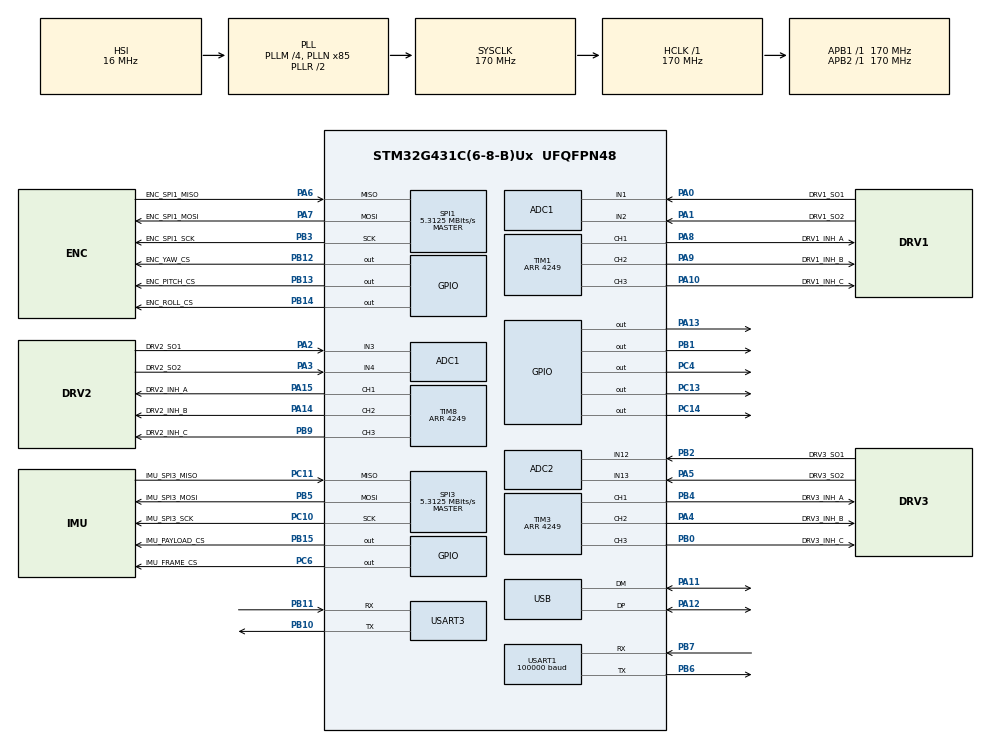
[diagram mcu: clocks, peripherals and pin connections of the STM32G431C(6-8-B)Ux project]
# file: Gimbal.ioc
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ADC1.DMAContinuousRequests=DISABLE
ADC1.EOCSelection=ADC_EOC_SEQ_CONV
ADC1.EnableInjectedConversion=ENABLE
ADC1.EnableRegularConversion=DISABLE
ADC1.ExternalTrigInjecConv=ADC_EXTERNALTRIGINJEC_T1_TRGO
ADC1.InjNumberOfConversion=2
ADC1.InjectedChannel-4\#ChannelInjectedConversion=ADC_CHANNEL_1
ADC1.InjectedChannel-5\#ChannelInjectedConversion=ADC_CHANNEL_2
ADC1.InjectedOffsetNumber-4\#ChannelInjectedConversion=ADC_OFFSET_NONE
ADC1.InjectedOffsetNumber-5\#ChannelInjectedConversion=ADC_OFFSET_NONE
ADC1.InjectedRank-4\#ChannelInjectedConversion=1
ADC1.InjectedRank-5\#ChannelInjectedConversion=2
ADC1.InjectedSamplingTime-4\#ChannelInjectedConversion=ADC_SAMPLETIME_12CYCLES_5
ADC1.InjectedSamplingTime-5\#ChannelInjectedConversion=ADC_SAMPLETIME_12CYCLES_5
ADC1.Overrun=ADC_OVR_DATA_OVERWRITTEN
ADC1.Rank1_Channel=ADC_CHANNEL_1
ADC1.Rank2_Channel=ADC_CHANNEL_2
ADC1.master=1
ADC2.EOCSelection=ADC_EOC_SEQ_CONV
ADC2.EnableInjectedConversion=ENABLE
ADC2.EnableRegularConversion=DISABLE
ADC2.ExternalTrigInjecConv=ADC_EXTERNALTRIGINJEC_T1_TRGO
ADC2.InjNumberOfConversion=2
ADC2.InjectedChannel-3\#ChannelInjectedConversion=ADC_CHANNEL_12
ADC2.InjectedChannel-4\#ChannelInjectedConversion=ADC_CHANNEL_13
ADC2.InjectedOffsetNumber-3\#ChannelInjectedConversion=ADC_OFFSET_NONE
ADC2.InjectedOffsetNumber-4\#ChannelInjectedConversion=ADC_OFFSET_NONE
ADC2.InjectedRank-3\#ChannelInjectedConversion=1
ADC2.InjectedRank-4\#ChannelInjectedConversion=2
ADC2.InjectedSamplingTime-3\#ChannelInjectedConversion=ADC_SAMPLETIME_12CYCLES_5
ADC2.InjectedSamplingTime-4\#ChannelInjectedConversion=ADC_SAMPLETIME_12CYCLES_5
ADC2.Rank1_Channel=ADC_CHANNEL_12
ADC2.Rank2_Channel=ADC_CHANNEL_13
Dma.Request0=SPI1_RX
Dma.Request1=SPI1_TX
Dma.Request2=SPI3_RX
Dma.Request3=SPI3_TX
Dma.Request4=USART1_RX
Dma.SPI1_RX.0.Direction=DMA_PERIPH_TO_MEMORY
Dma.SPI1_RX.0.EventEnable=DISABLE
Dma.SPI1_RX.0.Instance=DMA1_Channel1
Dma.SPI1_RX.0.MemDataAlignment=DMA_MDATAALIGN_HALFWORD
Dma.SPI1_RX.0.MemInc=DMA_MINC_ENABLE
Dma.SPI1_RX.0.Mode=DMA_NORMAL
Dma.SPI1_RX.0.PeriphDataAlignment=DMA_PDATAALIGN_HALFWORD
Dma.SPI1_RX.0.PeriphInc=DMA_PINC_DISABLE
Dma.SPI1_RX.0.Polarity=HAL_DMAMUX_REQ_GEN_RISING
Dma.SPI1_RX.0.Priority=DMA_PRIORITY_LOW
Dma.SPI1_RX.0.RequestNumber=1
Dma.SPI1_RX.0.SignalID=NONE
Dma.SPI1_RX.0.SyncEnable=DISABLE
Dma.SPI1_RX.0.SyncPolarity=HAL_DMAMUX_SYNC_NO_EVENT
Dma.SPI1_RX.0.SyncRequestNumber=1
Dma.SPI1_RX.0.SyncSignalID=NONE
Dma.SPI1_TX.1.Direction=DMA_MEMORY_TO_PERIPH
Dma.SPI1_TX.1.EventEnable=DISABLE
Dma.SPI1_TX.1.Instance=DMA1_Channel2
Dma.SPI1_TX.1.MemDataAlignment=DMA_MDATAALIGN_HALFWORD
Dma.SPI1_TX.1.MemInc=DMA_MINC_ENABLE
Dma.SPI1_TX.1.Mode=DMA_NORMAL
Dma.SPI1_TX.1.PeriphDataAlignment=DMA_PDATAALIGN_HALFWORD
Dma.SPI1_TX.1.PeriphInc=DMA_PINC_DISABLE
Dma.SPI1_TX.1.Polarity=HAL_DMAMUX_REQ_GEN_RISING
Dma.SPI1_TX.1.Priority=DMA_PRIORITY_LOW
Dma.SPI1_TX.1.RequestNumber=1
Dma.SPI1_TX.1.SignalID=NONE
Dma.SPI1_TX.1.SyncEnable=DISABLE
Dma.SPI1_TX.1.SyncPolarity=HAL_DMAMUX_SYNC_NO_EVENT
Dma.SPI1_TX.1.SyncRequestNumber=1
Dma.SPI1_TX.1.SyncSignalID=NONE
Dma.SPI3_RX.2.Direction=DMA_PERIPH_TO_MEMORY
Dma.SPI3_RX.2.EventEnable=DISABLE
Dma.SPI3_RX.2.Instance=DMA1_Channel3
Dma.SPI3_RX.2.MemDataAlignment=DMA_MDATAALIGN_BYTE
Dma.SPI3_RX.2.MemInc=DMA_MINC_ENABLE
Dma.SPI3_RX.2.Mode=DMA_NORMAL
Dma.SPI3_RX.2.PeriphDataAlignment=DMA_PDATAALIGN_BYTE
Dma.SPI3_RX.2.PeriphInc=DMA_PINC_DISABLE
Dma.SPI3_RX.2.Polarity=HAL_DMAMUX_REQ_GEN_RISING
Dma.SPI3_RX.2.Priority=DMA_PRIORITY_LOW
Dma.SPI3_RX.2.RequestNumber=1
Dma.SPI3_RX.2.SignalID=NONE
Dma.SPI3_RX.2.SyncEnable=DISABLE
Dma.SPI3_RX.2.SyncPolarity=HAL_DMAMUX_SYNC_NO_EVENT
Dma.SPI3_RX.2.SyncRequestNumber=1
Dma.SPI3_RX.2.SyncSignalID=NONE
Dma.SPI3_TX.3.Direction=DMA_MEMORY_TO_PERIPH
Dma.SPI3_TX.3.EventEnable=DISABLE
Dma.SPI3_TX.3.Instance=DMA1_Channel4
Dma.SPI3_TX.3.MemDataAlignment=DMA_MDATAALIGN_BYTE
Dma.SPI3_TX.3.MemInc=DMA_MINC_ENABLE
Dma.SPI3_TX.3.Mode=DMA_NORMAL
Dma.SPI3_TX.3.PeriphDataAlignment=DMA_PDATAALIGN_BYTE
Dma.SPI3_TX.3.PeriphInc=DMA_PINC_DISABLE
Dma.SPI3_TX.3.Polarity=HAL_DMAMUX_REQ_GEN_RISING
Dma.SPI3_TX.3.Priority=DMA_PRIORITY_LOW
Dma.SPI3_TX.3.RequestNumber=1
Dma.SPI3_TX.3.SignalID=NONE
Dma.SPI3_TX.3.SyncEnable=DISABLE
Dma.SPI3_TX.3.SyncPolarity=HAL_DMAMUX_SYNC_NO_EVENT
Dma.SPI3_TX.3.SyncRequestNumber=1
Dma.SPI3_TX.3.SyncSignalID=NONE
Dma.USART1_RX.4.Direction=DMA_PERIPH_TO_MEMORY
Dma.USART1_RX.4.EventEnable=DISABLE
Dma.USART1_RX.4.Instance=DMA1_Channel5
Dma.USART1_RX.4.MemDataAlignment=DMA_MDATAALIGN_BYTE
Dma.USART1_RX.4.MemInc=DMA_MINC_ENABLE
Dma.USART1_RX.4.Mode=DMA_CIRCULAR
Dma.USART1_RX.4.PeriphDataAlignment=DMA_PDATAALIGN_BYTE
Dma.USART1_RX.4.PeriphInc=DMA_PINC_DISABLE
Dma.USART1_RX.4.Polarity=HAL_DMAMUX_REQ_GEN_RISING
Dma.USART1_RX.4.Priority=DMA_PRIORITY_LOW
Dma.USART1_RX.4.RequestNumber=1
Dma.USART1_RX.4.SignalID=NONE
Dma.USART1_RX.4.SyncEnable=DISABLE
Dma.USART1_RX.4.SyncPolarity=HAL_DMAMUX_SYNC_NO_EVENT
Dma.USART1_RX.4.SyncRequestNumber=1
Dma.USART1_RX.4.SyncSignalID=NONE
Mcu.Family=STM32G4
Mcu.Name=STM32G431C(6-8-B)Ux
Mcu.Package=UFQFPN48
NVIC.ADC1_2_IRQn=true\:1\:0\:true\:false\:true\:true\:true\:true
NVIC.DMA1_Channel1_IRQn=true\:2\:0\:true\:false\:true\:false\:true\:true
NVIC.DMA1_Channel2_IRQn=true\:2\:0\:true\:false\:true\:false\:true\:true
NVIC.DMA1_Channel3_IRQn=true\:2\:0\:true\:false\:true\:false\:true\:true
NVIC.DMA1_Channel4_IRQn=true\:2\:0\:true\:false\:true\:false\:true\:true
NVIC.DMA1_Channel5_IRQn=true\:0\:0\:false\:false\:true\:false\:true\:true
NVIC.PriorityGroup=NVIC_PRIORITYGROUP_4
NVIC.SPI1_IRQn=true\:2\:0\:true\:false\:true\:true\:true\:true
NVIC.SPI3_IRQn=true\:2\:0\:true\:false\:true\:true\:true\:true
NVIC.TIM1_UP_TIM16_IRQn=true\:3\:0\:true\:false\:true\:true\:true\:true
NVIC.TIM6_DAC_IRQn=true\:2\:0\:true\:false\:true\:true\:true\:true
NVIC.TIM7_IRQn=true\:3\:0\:true\:false\:true\:true\:true\:true
NVIC.USART1_IRQn=true\:0\:0\:false\:false\:true\:true\:true\:true
NVIC.USB_LP_IRQn=true\:0\:0\:false\:false\:true\:false\:true\:true
PA0.GPIO_Label=DRV1_SO1
PA0.Mode=IN1-Single-Ended
PA0.Signal=ADC1_IN1
PA1.GPIO_Label=DRV1_SO2
PA1.Mode=IN2-Single-Ended
PA1.Signal=ADC1_IN2
PA10.GPIO_Label=DRV1_INH_C
PA10.Signal=S_TIM1_CH3
PA11.Mode=Device
PA11.Signal=USB_DM
PA12.Mode=Device
PA12.Signal=USB_DP
PA13.Signal=GPIO_Output
PA14.GPIO_Label=DRV2_INH_B
PA14.Signal=S_TIM8_CH2
PA15.GPIO_Label=DRV2_INH_A
PA15.Signal=S_TIM8_CH1
PA2.GPIO_Label=DRV2_SO1
PA2.Mode=IN3-Single-Ended
PA2.Signal=ADC1_IN3
PA3.GPIO_Label=DRV2_SO2
PA3.Mode=IN4-Single-Ended
PA3.Signal=ADC1_IN4
PA4.GPIO_Label=DRV3_INH_B
PA4.Signal=S_TIM3_CH2
PA5.GPIO_Label=DRV3_SO2
PA5.Mode=IN13-Single-Ended
PA5.Signal=ADC2_IN13
PA6.GPIO_Label=ENC_SPI1_MISO
PA6.Mode=Full_Duplex_Master
PA6.Signal=SPI1_MISO
PA7.GPIO_Label=ENC_SPI1_MOSI
PA7.Mode=Full_Duplex_Master
PA7.Signal=SPI1_MOSI
PA8.GPIO_Label=DRV1_INH_A
PA8.Signal=S_TIM1_CH1
PA9.GPIO_Label=DRV1_INH_B
PA9.Signal=S_TIM1_CH2
PB0.GPIO_Label=DRV3_INH_C
PB0.Signal=S_TIM3_CH3
PB1.PinState=GPIO_PIN_SET
PB1.Signal=GPIO_Output
PB10.Mode=Asynchronous
PB10.Signal=USART3_TX
PB11.Mode=Asynchronous
PB11.Signal=USART3_RX
PB12.GPIO_Label=ENC_YAW_CS
PB12.PinState=GPIO_PIN_SET
PB12.Signal=GPIO_Output
PB13.GPIO_Label=ENC_PITCH_CS
PB13.PinState=GPIO_PIN_SET
PB13.Signal=GPIO_Output
PB14.GPIO_Label=ENC_ROLL_CS
PB14.Signal=GPIO_Output
PB15.GPIO_Label=IMU_PAYLOAD_CS
PB15.PinState=GPIO_PIN_SET
PB15.Signal=GPIO_Output
PB2.GPIO_Label=DRV3_SO1
PB2.Mode=IN12-Single-Ended
PB2.Signal=ADC2_IN12
PB3.GPIO_Label=ENC_SPI1_SCK
PB3.Mode=Full_Duplex_Master
PB3.Signal=SPI1_SCK
PB4.GPIO_Label=DRV3_INH_A
PB4.Signal=S_TIM3_CH1
PB5.GPIO_Label=IMU_SPI3_MOSI
PB5.Mode=Full_Duplex_Master
PB5.Signal=SPI3_MOSI
PB6.Mode=Asynchronous
PB6.Signal=USART1_TX
PB7.Mode=Asynchronous
PB7.Signal=USART1_RX
PB9.GPIO_Label=DRV2_INH_C
PB9.Signal=S_TIM8_CH3
PC10.GPIO_Label=IMU_SPI3_SCK
PC10.Mode=Full_Duplex_Master
PC10.Signal=SPI3_SCK
PC11.GPIO_Label=IMU_SPI3_MISO
PC11.Mode=Full_Duplex_Master
PC11.Signal=SPI3_MISO
PC13.Signal=GPIO_Output
PC14-OSC32_IN.PinState=GPIO_PIN_SET
PC14-OSC32_IN.Signal=GPIO_Output
PC4.PinState=GPIO_PIN_SET
PC4.Signal=GPIO_Output
PC6.GPIO_Label=IMU_FRAME_CS
PC6.PinState=GPIO_PIN_SET
PC6.Signal=GPIO_Output
ProjectManager.HeapSize=0x200
ProjectManager.StackSize=0x400
ProjectManager.TargetToolchain=CMake
RCC.ADC12Freq_Value=170000000
RCC.AHBFreq_Value=170000000
RCC.APB1Freq_Value=170000000
RCC.APB1TimFreq_Value=170000000
RCC.APB2Freq_Value=170000000
RCC.APB2TimFreq_Value=170000000
RCC.CK48CLockSelection=RCC_USBCLKSOURCE_HSI48
RCC.CortexFreq_Value=170000000
RCC.EXTERNAL_CLOCK_VALUE=12288000
RCC.HCLKFreq_Value=170000000
RCC.HSE_VALUE=8000000
RCC.HSI48_VALUE=48000000
RCC.HSI_VALUE=16000000
RCC.LSE_VALUE=32768
RCC.PLLM=RCC_PLLM_DIV4
RCC.PLLN=85
RCC.PLLQ=RCC_PLLQ_DIV4
RCC.SYSCLKFreq_VALUE=170000000
RCC.SYSCLKSource=RCC_SYSCLKSOURCE_PLLCLK
RCC.USBFreq_Value=48000000
RCC.VCOOutputFreq_Value=340000000
SH.S_TIM1_CH1.0=TIM1_CH1,PWM Generation1 CH1
SH.S_TIM1_CH2.0=TIM1_CH2,PWM Generation2 CH2
SH.S_TIM1_CH3.0=TIM1_CH3,PWM Generation3 CH3
SH.S_TIM3_CH1.0=TIM3_CH1,PWM Generation1 CH1
SH.S_TIM3_CH2.0=TIM3_CH2,PWM Generation2 CH2
SH.S_TIM3_CH3.0=TIM3_CH3,PWM Generation3 CH3
SH.S_TIM8_CH1.0=TIM8_CH1,PWM Generation1 CH1
SH.S_TIM8_CH2.0=TIM8_CH2,PWM Generation2 CH2
SH.S_TIM8_CH3.0=TIM8_CH3,PWM Generation3 CH3
SPI1.BaudRatePrescaler=SPI_BAUDRATEPRESCALER_32
SPI1.CLKPhase=SPI_PHASE_2EDGE
SPI1.CalculateBaudRate=5.3125 MBits/s
SPI1.DataSize=SPI_DATASIZE_16BIT
SPI1.Direction=SPI_DIRECTION_2LINES
SPI1.Mode=SPI_MODE_MASTER
SPI1.VirtualType=VM_MASTER
SPI3.BaudRatePrescaler=SPI_BAUDRATEPRESCALER_32
SPI3.CLKPhase=SPI_PHASE_2EDGE
SPI3.CLKPolarity=SPI_POLARITY_HIGH
SPI3.CalculateBaudRate=5.3125 MBits/s
SPI3.DataSize=SPI_DATASIZE_8BIT
SPI3.Direction=SPI_DIRECTION_2LINES
SPI3.Mode=SPI_MODE_MASTER
SPI3.VirtualType=VM_MASTER
TIM1.AutoReloadPreload=TIM_AUTORELOAD_PRELOAD_ENABLE
TIM1.Channel-PWM\ Generation1\ CH1=TIM_CHANNEL_1
TIM1.Channel-PWM\ Generation2\ CH2=TIM_CHANNEL_2
TIM1.Channel-PWM\ Generation3\ CH3=TIM_CHANNEL_3
TIM1.Channel-PWM\ Generation4\ No\ Output=TIM_CHANNEL_4
TIM1.CounterMode=TIM_COUNTERMODE_CENTERALIGNED3
TIM1.PeriodNoDither=4249
TIM1.PulseNoDither_4=2125
TIM1.TIM_MasterOutputTrigger=TIM_TRGO_OC4REF
TIM1.TIM_MasterOutputTrigger2=TIM_TRGO2_RESET
TIM16.PeriodNoDither=1999
TIM16.Prescaler=169
TIM3.AutoReloadPreload=TIM_AUTORELOAD_PRELOAD_ENABLE
TIM3.Channel-PWM\ Generation1\ CH1=TIM_CHANNEL_1
TIM3.Channel-PWM\ Generation2\ CH2=TIM_CHANNEL_2
TIM3.Channel-PWM\ Generation3\ CH3=TIM_CHANNEL_3
TIM3.CounterMode=TIM_COUNTERMODE_CENTERALIGNED3
TIM3.PeriodNoDither=4249
TIM6.PeriodNoDither=499
TIM6.Prescaler=169
TIM7.PeriodNoDither=499
TIM7.Prescaler=169
TIM8.AutoReloadPreload=TIM_AUTORELOAD_PRELOAD_ENABLE
TIM8.Channel-PWM\ Generation1\ CH1=TIM_CHANNEL_1
TIM8.Channel-PWM\ Generation2\ CH2=TIM_CHANNEL_2
TIM8.Channel-PWM\ Generation3\ CH3=TIM_CHANNEL_3
TIM8.CounterMode=TIM_COUNTERMODE_CENTERALIGNED3
TIM8.PeriodNoDither=4249
USART1.BaudRate=100000
USART1.Parity=PARITY_EVEN
USART1.RxPinLevelInvertParam=ADVFEATURE_RXINV_ENABLE
USART1.StopBits=STOPBITS_2
USART1.VirtualMode-Asynchronous=VM_ASYNC
USART1.WordLength=WORDLENGTH_9B
USART3.VirtualMode-Asynchronous=VM_ASYNC
USB_DEVICE.CLASS_NAME_FS=CDC
USB_DEVICE.VirtualMode=Cdc
USB_DEVICE.VirtualModeFS=Cdc_FS
VP_SYS_VS_DBSignals.Mode=DisableDeadBatterySignals
VP_TIM16_VS_ClockSourceINT.Mode=Enable_Timer
VP_TIM1_VS_ClockSourceINT.Mode=Internal
VP_TIM1_VS_no_output4.Mode=PWM Generation4 No Output
VP_TIM3_VS_ClockSourceINT.Mode=Internal
VP_TIM6_VS_ClockSourceINT.Mode=Enable_Timer
VP_TIM7_VS_ClockSourceINT.Mode=Enable_Timer
VP_TIM8_VS_ClockSourceINT.Mode=Internal
VP_USB_DEVICE_VS_USB_DEVICE_CDC_FS.Mode=CDC_FS
board=custom

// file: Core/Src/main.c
/* USER CODE BEGIN Header */

/* USER CODE END Header */
#include "main.h"
#include "adc.h"
#include "dma.h"
#include "spi.h"
#include "tim.h"
#include "usart.h"
#include "usb_device.h"
#include "gpio.h"

/* USER CODE BEGIN Includes */
#include "as5048a.h"
#include "foc_v1.h"
#include "icm42688.h"
#include "imu_filter.h"
#include "mapping_sbus_channel.h"
#include "sbus_protocol.h"
#include <stdio.h>
#include <stdlib.h>
#include <string.h>

/* USER CODE END Includes */

/* USER CODE BEGIN PTD */
#define USE_EULER_ANGLE_CONTROL 1 /* 1: Dùng Euler, 0: Dùng Quaternion cho vòng ngoài */
/* USER CODE END PTD */

/* USER CODE BEGIN PD */

/* === Giới hạn góc mềm trục motor === */
#define MOTOR_PITCH_MIN_DEG 15.0f
#define MOTOR_PITCH_MAX_DEG 280.0f
#define MOTOR_ROLL_MIN_DEG 90.0f
#define MOTOR_ROLL_MAX_DEG 325.0f
#define MOTOR_YAW_MIN_DEG 65.0f
#define MOTOR_YAW_MAX_DEG 255.0f
#define MOTOR_YAW_FORBIDDEN_MIN_DEG 65.0f
#define MOTOR_YAW_FORBIDDEN_MAX_DEG 225.0f

/*=== Vị trí Home motor (khởi động tự động quay về đây) ===*/
#define HOME_MOTOR_ROLL_DEG 312.0f
#define HOME_MOTOR_PITCH_DEG 25.0f
#define HOME_MOTOR_YAW_DEG 340.0f
#define HOME_MOTOR_TOL_DEG 2.0f /* Sai số cho phép để coi là đã đến home_MOTOR (deg) */
#define HOME_MOTOR_TIMEOUT_MS 12000 /* Tối đa 12 giây để homing */

/*=== Góc mục tiêu cố định motor (dự phòng) ===*/
#define MOTOR_PITCH_SETPOINT_DEG 220.0f
#define MOTOR_ROLL_SETPOINT_DEG 185.0f
#define MOTOR_YAW_SETPOINT_DEG 180.0f

/*=== Góc mục tiêu của IMU ===*/
#define IMU_PITCH_TARGET_DEG 0.0f
#define IMU_ROLL_TARGET_DEG 0.0f
#define IMU_YAW_TARGET_DEG 150.0f

/*=== Cấu hình phần cứng mạch dòng ===*/
#define GAIN_DRV 10.0f
#define SHUNT_RES 0.005f
#define VOLTAGE_LIMIT 3.0f
#define PITCH_VOLTAGE_LIMIT 2.0f
#define ROLL_VOLTAGE_LIMIT 6.0f
#define YAW_VOLTAGE_LIMIT 6.0f
#define PWM_PERIOD 4249.0f
#define MOTOR_POLE_PAIRS 7

#define PI 3.14159265359f
#define TWO_PI 6.28318530718f
#define DEG_TO_RAD 0.0174532925f
#define RAD_TO_DEG 57.2957795f
#define DEG2RAD(d) ((d) * DEG_TO_RAD)

/* USER CODE END PD */

/* USER CODE BEGIN PM */
#define PROGRAM_MODE_MAIN 0
#define PROGRAM_MODE_IMU_TEST 1
#define PROGRAM_MODE_3AXIS_FOLLOW_IMU 2
#define PROGRAM_MODE_3AXIS_IMU_ON_FRAME 3
#define PROGRAM_MODE_TEST_VELOCITY 4
#define PROGRAM_MODE_TEST_SBUS 5
#define PROGRAM_MODE_3AXIS_FOLLOW_IMU_SBUS 6
#define PROGRAM_MODE PROGRAM_MODE_3AXIS_FOLLOW_IMU
/* USER CODE END PM */

/* USER CODE BEGIN PV */

AS5048A_Handle_t motor_pitch_enc;
AS5048A_Handle_t motor_roll_enc;
AS5048A_Handle_t motor_yaw_enc;
FOC_Handle_t foc_motor_pitch;
FOC_Handle_t foc_motor_roll;
FOC_Handle_t foc_motor_yaw;

ICM42688_Handle_t imu_payload;
MahonyFilter_t mahony_imu;
uint8_t icm_init_ok = 0;

Quaternion_t q_demo3_target; /* Hướng mục tiêu: chốt khi vào mode, giữ cố định sau đó */

/* PID vòng ngoài: error góc (rad) → velo setpoint (rad/s) cho từng trục */
PID_Handle_t pid_motor_roll_pos;
PID_Handle_t pid_motor_pitch_pos;
PID_Handle_t pid_motor_yaw_pos;

PID_Handle_t pid_imu_roll_pos;
PID_Handle_t pid_imu_pitch_pos;
PID_Handle_t pid_imu_yaw_pos;

SBUS_Handle_t sbus_rx;
SBUS_Mapping_Handle_t sbus_map; /* Mapping SBUS raw → target angle gimbal */

volatile float target_motor_pitch_angle = 0.0f;
volatile float target_motor_roll_angle = 0.0f;
volatile float target_motor_yaw_angle = 0.0f;

volatile float imu_stab_vel_roll = 0.0f;
volatile float imu_stab_vel_pitch = 0.0f;
volatile float imu_stab_vel_yaw = 0.0f;

/* Góc IMU chốt lúc startup — giữ cố định làm target ổn định (dùng trong 3AXIS_FOLLOW_IMU) */
volatile float imu_pitch_target_rad = 0.0f;
volatile float imu_roll_target_rad = 0.0f;
volatile float imu_yaw_target_rad   = 0.0f;

/* IMU_ON_FRAME: điểm tham chiếu khởi động — đo lượng frame lệch bao nhiêu */
volatile float imu_pitch_init_rad    = 0.0f;  /* Góc pitch IMU lúc khởi động [rad] */
volatile float imu_roll_init_rad    = 0.0f;  /* Góc roll IMU lúc khởi động [rad] */
volatile float imu_yaw_init_rad      = 0.0f;  /* Góc yaw IMU lúc khởi động [rad] */
volatile float motor_pitch_init_rad  = 0.0f;  /* Vị trí encoder Pitch lúc khởi động [rad] */
volatile float motor_roll_init_rad  = 0.0f;  /* Vị trí encoder Roll lúc khởi động [rad] */
volatile float motor_yaw_init_rad    = 0.0f;  /* Vị trí encoder Yaw lúc khởi động [rad] */
volatile float target_motor_pitch_imu = 0.0f; /* Target motor Pitch cập nhật theo delta IMU [rad] */
volatile float target_motor_roll_imu = 0.0f; /* Target motor Roll cập nhật theo delta IMU [rad] */
volatile float target_motor_yaw_imu   = 0.0f; /* Target motor Yaw cập nhật theo delta IMU [rad] */

/* === Trạng thái máy trạng thái của gimbal === */
typedef enum {
  GIMBAL_STATE_HOMING = 0,
  GIMBAL_STATE_SBUS,
  GIMBAL_STATE_IMU_STAB,
} GimbalState_t;
GimbalState_t g_gimbal_state = GIMBAL_STATE_HOMING;

/* USER CODE END PV */

void SystemClock_Config(void);

int main(void)
{

  /* MCU Configuration--------------------------------------------------------*/

  /* Reset of all peripherals, Initializes the Flash interface and the Systick. */
  HAL_Init();

  /* Configure the system clock */
  SystemClock_Config();

  /* Initialize all configured peripherals */
  MX_GPIO_Init();
  MX_DMA_Init();
  MX_USB_Device_Init();
  MX_SPI1_Init();
  MX_TIM6_Init();
  MX_TIM3_Init();
  MX_ADC1_Init();
  MX_ADC2_Init();
  MX_TIM1_Init();
  MX_TIM8_Init();
  MX_SPI3_Init();
  MX_USART1_UART_Init();
  MX_USART3_UART_Init();
  MX_TIM7_Init();
  MX_TIM16_Init();
  /* USER CODE BEGIN 2 */
  uint32_t last_print_time = HAL_GetTick();

#if (PROGRAM_MODE == PROGRAM_MODE_MAIN)

  HAL_GPIO_WritePin(GPIOB, GPIO_PIN_1, GPIO_PIN_SET);

  /*=== Khởi tạo encoder ===*/
  AS5048A_Init(&motor_pitch_enc, &hspi1, ENC_PITCH_CS_GPIO_Port, ENC_PITCH_CS_Pin);
  AS5048A_Init(&motor_roll_enc, &hspi1, ENC_ROLL_CS_GPIO_Port, ENC_ROLL_CS_Pin);
  AS5048A_Init(&motor_yaw_enc, &hspi1, ENC_YAW_CS_GPIO_Port, ENC_YAW_CS_Pin);
  HAL_GPIO_WritePin(ENC_PITCH_CS_GPIO_Port, ENC_PITCH_CS_Pin, GPIO_PIN_SET);
  HAL_GPIO_WritePin(ENC_ROLL_CS_GPIO_Port, ENC_ROLL_CS_Pin, GPIO_PIN_SET);
  HAL_GPIO_WritePin(ENC_YAW_CS_GPIO_Port, ENC_YAW_CS_Pin, GPIO_PIN_SET);

  HAL_TIM_Base_Start_IT(&htim6); // TIMER 6 dùng để đọc các ngoại vi như encoder và IMU
  HAL_Delay(100); // Chờ lấy mẫu vài frame góc ban đầu từ AS5048A

  /*=== Khởi tạo trục Pitch ===*/
  FOC_Init(&foc_motor_pitch, &htim3, TIM_CHANNEL_1, TIM_CHANNEL_2, TIM_CHANNEL_3,
           PWM_PERIOD, MOTOR_POLE_PAIRS, 12.0f, /* voltage_supply: Bus DC 12V */
           VOLTAGE_LIMIT, 1.0f, 0.0005f, 0.00005f);
  HAL_TIM_PWM_Start(&htim3, TIM_CHANNEL_1);
  HAL_TIM_PWM_Start(&htim3, TIM_CHANNEL_2);
  HAL_TIM_PWM_Start(&htim3, TIM_CHANNEL_3);
  FOC_SetPID_POS(&foc_motor_pitch, 6.0f, 0.4f, 0.0f, -3.0f, 3.0f);
  FOC_SetPID_VEL(&foc_motor_pitch, 0.4f, 0.0f, 0.0f, -VOLTAGE_LIMIT, VOLTAGE_LIMIT);
  FOC_SetLPF_Vel(&foc_motor_pitch, 0.96f);

  // /*=== Khởi tạo trục Roll ===*/
  FOC_Init(&foc_motor_roll, &htim8, TIM_CHANNEL_1, TIM_CHANNEL_2, TIM_CHANNEL_3,
           PWM_PERIOD, MOTOR_POLE_PAIRS, 12.0f, VOLTAGE_LIMIT, 1.0f, 0.0005f,
           0.00005f);
  // HAL_TIM_PWM_Start(&htim8, TIM_CHANNEL_1);
  // HAL_TIM_PWM_Start(&htim8, TIM_CHANNEL_2);
  // HAL_TIM_PWM_Start(&htim8, TIM_CHANNEL_3);
  FOC_SetPID_POS(&foc_motor_roll, 8.0f, 0.4f, 0.0f, -4.0f, 4.0f);
  FOC_SetPID_VEL(&foc_motor_roll, 0.4f, 5.0f, 0.0f, -VOLTAGE_LIMIT, VOLTAGE_LIMIT);
  FOC_SetLPF_Vel(&foc_motor_roll, 0.96f);

  /*=== Khởi tạo trục Yaw ===*/
  FOC_Init(&foc_motor_yaw, &htim1, TIM_CHANNEL_1, TIM_CHANNEL_2, TIM_CHANNEL_3,
           PWM_PERIOD, MOTOR_POLE_PAIRS, 12.0f, VOLTAGE_LIMIT, 1.0f, 0.0005f,
           0.00005f);
  HAL_TIM_PWM_Start(&htim1, TIM_CHANNEL_1);
  HAL_TIM_PWM_Start(&htim1, TIM_CHANNEL_2);
  HAL_TIM_PWM_Start(&htim1, TIM_CHANNEL_3);
  FOC_SetPID_POS(&foc_motor_yaw, 6.0f, 0.4f, 0.0f, -3.0f, 3.0f);
  FOC_SetPID_VEL(&foc_motor_yaw, 0.4f, 0.0f, 0.0f, -VOLTAGE_LIMIT, VOLTAGE_LIMIT);
  FOC_SetLPF_Vel(&foc_motor_yaw, 0.96f);

  foc_motor_pitch.enabled = 1;
  foc_motor_roll.enabled = 1;
  foc_motor_yaw.enabled = 1;

  FOC_AlignD(&foc_motor_pitch, 1.0f);
  FOC_AlignD(&foc_motor_roll, 1.0f);
  FOC_AlignD(&foc_motor_yaw, 1.0f);
  HAL_Delay(1000);

  FOC_CalibrateAngle(&foc_motor_pitch, motor_pitch_enc.angle_rad);
  FOC_CalibrateAngle(&foc_motor_roll, motor_roll_enc.angle_rad);
  FOC_CalibrateAngle(&foc_motor_yaw, motor_yaw_enc.angle_rad);

  FOC_Start(&foc_motor_pitch, motor_pitch_enc.angle_rad);
  FOC_Start(&foc_motor_roll, motor_roll_enc.angle_rad);
  FOC_Start(&foc_motor_yaw, motor_yaw_enc.angle_rad);

  /*=== Khởi tạo IMU ===*/
  ICM42688_Status_t imu_status = ICM42688_Init(&imu_payload, &hspi3, GPIOC, GPIO_PIN_6, NULL);
  if (imu_status == ICM42688_OK) {
    icm_init_ok = 1;
    ICM42688_CalibrateGyroBias(&imu_payload, 500);
    Mahony_Init(&mahony_imu, 1.0f, 0.005f);
    HAL_Delay(2000);
    printf("[IMU] AHRS hien tai: R=%.2f P=%.2f Y=%.2f (deg)\r\n",
           mahony_imu.roll * RAD_TO_DEG,
           mahony_imu.pitch * RAD_TO_DEG,
           mahony_imu.yaw * RAD_TO_DEG);
  } else {
    icm_init_ok = 0;
    printf("[IMU] LOI khoi tao ICM42688! Code: %d\r\n", imu_status);
  }

  HAL_TIM_Base_Start_IT(&htim16); // Outer PID
  HAL_TIM_Base_Start_IT(&htim7);  // Inner PID

  SBUS_Status_t sbus_init_ret = SBUS_Init(&sbus_rx, &huart1);
  if (sbus_init_ret == SBUS_OK) {
    printf("[SBUS] Khoi tao thanh cong!\r\n");
  } else {
    printf("[SBUS] LOI khoi tao! Check USART1 DMA config.\r\n");
  }

  /* Đặt target về vị trí HOME — TIM7 ISR sẽ tự động drive motor đến đây */
  target_motor_roll_angle = DEG2RAD(HOME_MOTOR_ROLL_DEG);
  target_motor_pitch_angle = DEG2RAD(HOME_MOTOR_PITCH_DEG);
  target_motor_yaw_angle = DEG2RAD(HOME_MOTOR_YAW_DEG);
  printf("[HOME] Bat dau Homing: Roll=%.1f Pitch=%.1f Yaw=%.1f (deg)\r\n",
         HOME_MOTOR_ROLL_DEG, HOME_MOTOR_PITCH_DEG, HOME_MOTOR_YAW_DEG);
#elif (PROGRAM_MODE == PROGRAM_MODE_IMU_TEST)
  HAL_GPIO_WritePin(GPIOC, GPIO_PIN_14, GPIO_PIN_SET);

  /*=== Khởi tạo IMU ICM42688 ===*/
  ICM42688_Status_t imu_status = ICM42688_Init(&imu_payload, &hspi3, GPIOC, GPIO_PIN_14, NULL);
  if (imu_status == ICM42688_OK) {
    icm_init_ok = 1;
    ICM42688_CalibrateGyroBias(&imu_payload, 500);
    Mahony_Init(&mahony_imu, 1.0f, 0.005f);
    printf("[IMU_TEST] Khoi tao ICM42688 thanh cong!\r\n");
  } else {
    icm_init_ok = 0;
    printf("[IMU_TEST] LOI khoi tao ICM42688! Code: %d\r\n", imu_status);
  }

  HAL_TIM_Base_Start_IT(&htim6); /* TIM6: kích hoạt SPI3 DMA đọc Burst 15-byte cho ICM42688 */
  HAL_Delay(100);

#elif (PROGRAM_MODE == PROGRAM_MODE_3AXIS_FOLLOW_IMU)
  HAL_GPIO_WritePin(GPIOB, GPIO_PIN_1, GPIO_PIN_SET);

  /*=== Khởi tạo encoder Pitch và Yaw ===*/
  AS5048A_Init(&motor_pitch_enc, &hspi1, ENC_PITCH_CS_GPIO_Port, ENC_PITCH_CS_Pin);
  AS5048A_Init(&motor_yaw_enc,   &hspi1, ENC_YAW_CS_GPIO_Port,   ENC_YAW_CS_Pin);
  HAL_GPIO_WritePin(ENC_PITCH_CS_GPIO_Port, ENC_PITCH_CS_Pin, GPIO_PIN_SET);
  HAL_GPIO_WritePin(ENC_YAW_CS_GPIO_Port,   ENC_YAW_CS_Pin,   GPIO_PIN_SET);

  HAL_TIM_Base_Start_IT(&htim6); /* TIM6: đọc encoder + trigger IMU DMA */
  HAL_Delay(100);                /* Chờ vài frame encoder ổn định */

  /*=== Khởi tạo FOC trục Pitch (TIM3) ===*/
  FOC_Init(&foc_motor_pitch, &htim3, TIM_CHANNEL_1, TIM_CHANNEL_2, TIM_CHANNEL_3,
           PWM_PERIOD, MOTOR_POLE_PAIRS, 12.0f, PITCH_VOLTAGE_LIMIT, 1.0f, 0.0005f, 0.00005f);
  HAL_TIM_PWM_Start(&htim3, TIM_CHANNEL_1);
  HAL_TIM_PWM_Start(&htim3, TIM_CHANNEL_2);
  HAL_TIM_PWM_Start(&htim3, TIM_CHANNEL_3);
  FOC_SetPID_VEL(&foc_motor_pitch, 1.0f, 0.1f, 0.0f, -PITCH_VOLTAGE_LIMIT, PITCH_VOLTAGE_LIMIT);
  FOC_SetLPF_Vel(&foc_motor_pitch, 0.96f);

  // /*=== Khởi tạo trục Roll ===*/
  FOC_Init(&foc_motor_roll, &htim8, TIM_CHANNEL_1, TIM_CHANNEL_2, TIM_CHANNEL_3,
           PWM_PERIOD, MOTOR_POLE_PAIRS, 12.0f, ROLL_VOLTAGE_LIMIT, 1.0f, 0.0005f, 0.00005f);
  HAL_TIM_PWM_Start(&htim8, TIM_CHANNEL_1);
  HAL_TIM_PWM_Start(&htim8, TIM_CHANNEL_2);
  HAL_TIM_PWM_Start(&htim8, TIM_CHANNEL_3);
  FOC_SetPID_VEL(&foc_motor_roll, 1.0f, 0.1f, 0.0f, -ROLL_VOLTAGE_LIMIT, ROLL_VOLTAGE_LIMIT);
  FOC_SetLPF_Vel(&foc_motor_roll, 0.96f);

  /*=== Khởi tạo FOC trục Yaw (TIM1) ===*/
  FOC_Init(&foc_motor_yaw, &htim1, TIM_CHANNEL_1, TIM_CHANNEL_2, TIM_CHANNEL_3,
           PWM_PERIOD, MOTOR_POLE_PAIRS, 12.0f, YAW_VOLTAGE_LIMIT, 1.0f, 0.0005f, 0.00005f);
  HAL_TIM_PWM_Start(&htim1, TIM_CHANNEL_1);
  HAL_TIM_PWM_Start(&htim1, TIM_CHANNEL_2);
  HAL_TIM_PWM_Start(&htim1, TIM_CHANNEL_3);
  FOC_SetPID_VEL(&foc_motor_yaw, 1.0f, 0.1f, 0.0f, -YAW_VOLTAGE_LIMIT, YAW_VOLTAGE_LIMIT);
  FOC_SetLPF_Vel(&foc_motor_yaw, 0.96f);

  foc_motor_pitch.enabled = 1;
  foc_motor_yaw.enabled   = 1;

  /*=== AlignD: kéo rotor về D-axis để calibrate angle offset ===*/
  FOC_AlignD(&foc_motor_pitch, 1.0f);
  FOC_AlignD(&foc_motor_roll, 1.0f);
  FOC_AlignD(&foc_motor_yaw,   1.0f);
  HAL_Delay(1000);

  FOC_CalibrateAngle(&foc_motor_pitch, motor_pitch_enc.angle_rad);
  FOC_CalibrateAngle(&foc_motor_roll, motor_roll_enc.angle_rad);
  FOC_CalibrateAngle(&foc_motor_yaw,   motor_yaw_enc.angle_rad);

  FOC_Start(&foc_motor_pitch, motor_pitch_enc.angle_rad);
  FOC_Start(&foc_motor_roll, motor_roll_enc.angle_rad);
  FOC_Start(&foc_motor_yaw,   motor_yaw_enc.angle_rad);

  /*=== Khởi tạo IMU ICM42688 ===*/
  ICM42688_Status_t imu_status3 = ICM42688_Init(&imu_payload, &hspi3, GPIOC, GPIO_PIN_14, NULL);
  if (imu_status3 == ICM42688_OK) {
    icm_init_ok = 1;
    ICM42688_CalibrateGyroBias(&imu_payload, 500);
    Mahony_Init(&mahony_imu, 1.0f, 0.005f);
    printf("[IMU] Khoi tao OK. Cho Mahony hoi tu (2s)...\r\n");
    HAL_Delay(2000); /* Chờ Mahony filter hội tụ */

    /* Chốt góc IMU hiện tại làm target ổn định (Dừ gimbal ở vị trí mong muốn trong 2s này!) */
    imu_pitch_target_rad = mahony_imu.pitch;
    imu_roll_target_rad = mahony_imu.roll;
    imu_yaw_target_rad   = mahony_imu.yaw;
    printf("[IMU] Target chot: Pitch=%.2f  Roll=%.2f  Yaw=%.2f (deg)\r\n",
           imu_pitch_target_rad * RAD_TO_DEG,
           imu_roll_target_rad * RAD_TO_DEG,
           imu_yaw_target_rad   * RAD_TO_DEG);
  } else {
    icm_init_ok = 0;
    printf("[IMU] LOI khoi tao! Code: %d\r\n", imu_status3);
  }

  /*=== Khởi tạo PID outer loop: IMU angle error → velocity setpoint [rad/s] ===*/
  PID_Init(&pid_imu_pitch_pos, 30.0f, 2.0f, 3.0f, -10.0f, 10.0f);
  PID_Init(&pid_imu_roll_pos, 30.0f, 5.0f, 10.0f, -8.0f, 8.0f);
  PID_Init(&pid_imu_yaw_pos,   30.0f, 5.0f, 10.0f, -8.0f, 8.0f);

  /*=== Khởi động timers điều khiển ===*/
  HAL_TIM_Base_Start_IT(&htim16); /* Outer PID @ 500Hz */
  HAL_TIM_Base_Start_IT(&htim7);  /* Inner FOC @ 2kHz  */
  printf("[3AXIS_IMU] San sang! Bat dau on dinh.\r\n");

#elif (PROGRAM_MODE == PROGRAM_MODE_3AXIS_IMU_ON_FRAME)
  HAL_GPIO_WritePin(GPIOB, GPIO_PIN_1, GPIO_PIN_SET);

  /*=== Khởi tạo encoder Pitch và Yaw ===*/
  AS5048A_Init(&motor_pitch_enc, &hspi1, ENC_PITCH_CS_GPIO_Port, ENC_PITCH_CS_Pin);
  AS5048A_Init(&motor_yaw_enc,   &hspi1, ENC_YAW_CS_GPIO_Port,   ENC_YAW_CS_Pin);
  HAL_GPIO_WritePin(ENC_PITCH_CS_GPIO_Port, ENC_PITCH_CS_Pin, GPIO_PIN_SET);
  HAL_GPIO_WritePin(ENC_YAW_CS_GPIO_Port,   ENC_YAW_CS_Pin,   GPIO_PIN_SET);

  HAL_TIM_Base_Start_IT(&htim6); /* TIM6: đọc encoder + trigger IMU DMA */
  HAL_Delay(100);                /* Chờ vài frame encoder ổn định */

  /*=== Khởi tạo FOC trục Pitch (TIM3) ===*/
  FOC_Init(&foc_motor_pitch, &htim3, TIM_CHANNEL_1, TIM_CHANNEL_2, TIM_CHANNEL_3,
           PWM_PERIOD, MOTOR_POLE_PAIRS, 12.0f, VOLTAGE_LIMIT, 1.0f, 0.0005f, 0.00005f);
  HAL_TIM_PWM_Start(&htim3, TIM_CHANNEL_1);
  HAL_TIM_PWM_Start(&htim3, TIM_CHANNEL_2);
  HAL_TIM_PWM_Start(&htim3, TIM_CHANNEL_3);
  FOC_SetPID_POS(&foc_motor_pitch, 18.0f, 0.4f, 0.0f, -3.0f, 3.0f);
  FOC_SetPID_VEL(&foc_motor_pitch, 20.0f, 0.0f, 0.0f, -VOLTAGE_LIMIT, VOLTAGE_LIMIT);
  FOC_SetLPF_Vel(&foc_motor_pitch, 0.96f);

  /*=== Khởi tạo FOC trục Roll (TIM8) ===*/
  FOC_Init(&foc_motor_roll, &htim8, TIM_CHANNEL_1, TIM_CHANNEL_2, TIM_CHANNEL_3,
           PWM_PERIOD, MOTOR_POLE_PAIRS, 12.0f, VOLTAGE_LIMIT, 1.0f, 0.0005f, 0.00005f);
  HAL_TIM_PWM_Start(&htim8, TIM_CHANNEL_1);
  HAL_TIM_PWM_Start(&htim8, TIM_CHANNEL_2);
  HAL_TIM_PWM_Start(&htim8, TIM_CHANNEL_3);
  FOC_SetPID_POS(&foc_motor_roll, 18.0f, 0.4f, 0.0f, -3.0f, 3.0f);
  FOC_SetPID_VEL(&foc_motor_roll, 20.0f, 0.0f, 0.0f, -VOLTAGE_LIMIT, VOLTAGE_LIMIT);
  FOC_SetLPF_Vel(&foc_motor_roll, 0.96f);

  /*=== Khởi tạo FOC trục Yaw (TIM1) ===*/
  FOC_Init(&foc_motor_yaw, &htim1, TIM_CHANNEL_1, TIM_CHANNEL_2, TIM_CHANNEL_3,
           PWM_PERIOD, MOTOR_POLE_PAIRS, 12.0f, VOLTAGE_LIMIT, 1.0f, 0.0005f, 0.00005f);
  HAL_TIM_PWM_Start(&htim1, TIM_CHANNEL_1);
  HAL_TIM_PWM_Start(&htim1, TIM_CHANNEL_2);
  HAL_TIM_PWM_Start(&htim1, TIM_CHANNEL_3);
  FOC_SetPID_POS(&foc_motor_yaw, 6.0f, 0.4f, 0.0f, -3.0f, 3.0f);
  FOC_SetPID_VEL(&foc_motor_yaw, 0.4f, 5.0f, 0.0f, -VOLTAGE_LIMIT, VOLTAGE_LIMIT);
  FOC_SetLPF_Vel(&foc_motor_yaw, 0.96f);

  foc_motor_pitch.enabled = 1;
  foc_motor_yaw.enabled   = 1;

  /*=== AlignD: kéo rotor về D-axis để calibrate angle offset ===*/
  FOC_AlignD(&foc_motor_pitch, 1.0f);
  FOC_AlignD(&foc_motor_roll, 1.0f);
  FOC_AlignD(&foc_motor_yaw,   1.0f);
  HAL_Delay(1000);

  FOC_CalibrateAngle(&foc_motor_pitch, motor_pitch_enc.angle_rad);
  FOC_CalibrateAngle(&foc_motor_roll, motor_roll_enc.angle_rad);
  FOC_CalibrateAngle(&foc_motor_yaw,   motor_yaw_enc.angle_rad);

  FOC_Start(&foc_motor_pitch, motor_pitch_enc.angle_rad);
  FOC_Start(&foc_motor_roll, motor_roll_enc.angle_rad);
  FOC_Start(&foc_motor_yaw,   motor_yaw_enc.angle_rad);

  /*=== Khởi tạo IMU ICM42688 ===*/
  ICM42688_Status_t imu_status4 = ICM42688_Init(&imu_payload, &hspi3, GPIOC, GPIO_PIN_6, NULL);
  if (imu_status4 == ICM42688_OK) {
    icm_init_ok = 1;
    ICM42688_CalibrateGyroBias(&imu_payload, 500);
    Mahony_Init(&mahony_imu, 1.0f, 0.005f);
    printf("[IMU_FRAME] Khoi tao OK. Cho Mahony hoi tu (2s)...\r\n");
    HAL_Delay(2000); /* Chờ Mahony filter hội tụ */

    /* Chốt điểm tham chiếu: góc IMU và encoder lúc khởi động */
    imu_pitch_init_rad   = mahony_imu.pitch;
    imu_roll_init_rad   = mahony_imu.roll;
    imu_yaw_init_rad     = mahony_imu.yaw;
    motor_pitch_init_rad = motor_pitch_enc.angle_rad;
    motor_roll_init_rad = motor_roll_enc.angle_rad;
    motor_yaw_init_rad   = motor_yaw_enc.angle_rad;

    /* Target ban đầu = vị trí encoder hiện tại (giữ nguyên khi mới bật) */
    target_motor_pitch_imu = motor_pitch_init_rad;
    target_motor_roll_imu = motor_roll_init_rad;
    target_motor_yaw_imu   = motor_yaw_init_rad;

    printf("[IMU_FRAME] Chot tham chieu: IMU P=%.2f R=%.2f Y=%.2f | ENC P=%.1f R=%.1f Y=%.1f (deg)\r\n",
           imu_pitch_init_rad * RAD_TO_DEG, imu_roll_init_rad * RAD_TO_DEG, imu_yaw_init_rad * RAD_TO_DEG,
           motor_pitch_enc.angle_deg, motor_roll_enc.angle_deg, motor_yaw_enc.angle_deg);
  } else {
    icm_init_ok = 0;
    printf("[IMU_FRAME] LOI khoi tao IMU! Code: %d\r\n", imu_status4);
  }

  /* Khởi động TIM7 (không cần TIM16 — target được tính trực tiếp trong TIM7) */
  HAL_TIM_Base_Start_IT(&htim7);  /* Inner FOC @ 2kHz */
  printf("[IMU_FRAME] San sang! Bat dau on dinh theo delta IMU.\r\n");
#elif (PROGRAM_MODE == PROGRAM_MODE_3AXIS_FOLLOW_IMU_SBUS)
#elif (PROGRAM_MODE == PROGRAM_MODE_TEST_VELOCITY)
  HAL_GPIO_WritePin(GPIOB, GPIO_PIN_1, GPIO_PIN_SET);
  /*=== Khởi tạo encoder ===*/
  AS5048A_Init(&motor_pitch_enc, &hspi1, ENC_PITCH_CS_GPIO_Port, ENC_PITCH_CS_Pin);
  AS5048A_Init(&motor_yaw_enc,   &hspi1, ENC_YAW_CS_GPIO_Port,   ENC_YAW_CS_Pin);
  HAL_GPIO_WritePin(ENC_PITCH_CS_GPIO_Port, ENC_PITCH_CS_Pin, GPIO_PIN_SET);
  HAL_GPIO_WritePin(ENC_YAW_CS_GPIO_Port,   ENC_YAW_CS_Pin,   GPIO_PIN_SET);
  HAL_TIM_Base_Start_IT(&htim6); /* TIM6: đọc encoder */
  HAL_Delay(100);

  /*=== Khởi tạo FOC trục Pitch ===*/
  FOC_Init(&foc_motor_pitch, &htim3, TIM_CHANNEL_1, TIM_CHANNEL_2, TIM_CHANNEL_3,
           PWM_PERIOD, MOTOR_POLE_PAIRS, 12.0f, VOLTAGE_LIMIT, 1.0f, 0.0005f, 0.00005f);
  HAL_TIM_PWM_Start(&htim3, TIM_CHANNEL_1);
  HAL_TIM_PWM_Start(&htim3, TIM_CHANNEL_2);
  HAL_TIM_PWM_Start(&htim3, TIM_CHANNEL_3);
  FOC_SetPID_VEL(&foc_motor_pitch, 0.4f, 5.0f, 0.0f, -VOLTAGE_LIMIT, VOLTAGE_LIMIT);
  FOC_SetLPF_Vel(&foc_motor_pitch, 0.96f);

  /*=== Khởi tạo FOC trục Yaw ===*/
  FOC_Init(&foc_motor_yaw, &htim1, TIM_CHANNEL_1, TIM_CHANNEL_2, TIM_CHANNEL_3,
           PWM_PERIOD, MOTOR_POLE_PAIRS, 12.0f, VOLTAGE_LIMIT, 1.0f, 0.0005f, 0.00005f);
  HAL_TIM_PWM_Start(&htim1, TIM_CHANNEL_1);
  HAL_TIM_PWM_Start(&htim1, TIM_CHANNEL_2);
  HAL_TIM_PWM_Start(&htim1, TIM_CHANNEL_3);
  FOC_SetPID_VEL(&foc_motor_yaw, 0.4f, 5.0f, 0.0f, -VOLTAGE_LIMIT, VOLTAGE_LIMIT);
  FOC_SetLPF_Vel(&foc_motor_yaw, 0.96f);

  foc_motor_pitch.enabled = 1;
  foc_motor_yaw.enabled   = 1;
  FOC_AlignD(&foc_motor_pitch, 1.0f);
  FOC_AlignD(&foc_motor_yaw,   1.0f);
  HAL_Delay(1000);
  FOC_CalibrateAngle(&foc_motor_pitch, motor_pitch_enc.angle_rad);
  FOC_CalibrateAngle(&foc_motor_yaw,   motor_yaw_enc.angle_rad);
  FOC_Start(&foc_motor_pitch, motor_pitch_enc.angle_rad);
  FOC_Start(&foc_motor_yaw,   motor_yaw_enc.angle_rad);

  HAL_TIM_Base_Start_IT(&htim7);  /* Inner FOC @ 2kHz */
  printf("[TEST_VELOCITY] San sang quay (1.0 rad/s)!\r\n");
#elif (PROGRAM_MODE == PROGRAM_MODE_TEST_SBUS)
  SBUS_Status_t sbus_init_ret = SBUS_Init(&sbus_rx, &huart1);
  if (sbus_init_ret == SBUS_OK) {
    printf("[SBUS] Khoi tao thanh cong! Dang cho tin hieu tu Receiver...\r\n");
  } else {
    printf(
        "[SBUS] LOI khoi tao! Check USART1 DMA config (100000 baud, 8E2).\r\n");
  }
#endif

  /* USER CODE END 2 */

  /* Infinite loop */
  /* USER CODE BEGIN WHILE */

  while (1) {
#if (PROGRAM_MODE == PROGRAM_MODE_MAIN)
    uint32_t now = HAL_GetTick();

    /* USER CODE END WHILE */

    /* USER CODE BEGIN 3 */
    if (now - last_print_time >= 100) {
      last_print_time = now;
    }

    printf(
          "[AHRS]  R:%5.2f P:%5.2f Y:%5.2f (deg) | [GYRO]  Gx:%5.2f Gy:%5.2f "
          "Gz:%5.2f (dps) | [ACCEL] Ax:%5.3f Ay:%5.3f Az:%5.3f (g) \r\n",
          mahony_imu.roll * RAD_TO_DEG, mahony_imu.pitch * RAD_TO_DEG,
          mahony_imu.yaw * RAD_TO_DEG, imu_payload.gyro_x_dps,
          imu_payload.gyro_y_dps, imu_payload.gyro_z_dps, imu_payload.accel_x_g,
          imu_payload.accel_y_g, imu_payload.accel_z_g);

    printf("[ENC] R:%6.1f P:%6.1f Y:%6.1f (deg) | [FORCE] R:%5.2f P:%5.2f Y:%5.2f (V)\r\n",
                 motor_roll_enc.angle_deg, motor_pitch_enc.angle_deg, motor_yaw_enc.angle_deg,
                 foc_motor_roll.Vq_ref, foc_motor_pitch.Vq_ref, foc_motor_yaw.Vq_ref);

    HAL_Delay(100);

#elif (PROGRAM_MODE == PROGRAM_MODE_IMU_TEST)
    uint32_t now = HAL_GetTick();
    if (now - last_print_time >= 100) {
      last_print_time = now;
      printf("[IMU_TEST] R:%5.2f P:%5.2f Y:%5.2f (deg) | Gx:%5.2f Gy:%5.2f Gz:%5.2f (dps)\r\n",
             mahony_imu.roll * RAD_TO_DEG, mahony_imu.pitch * RAD_TO_DEG, mahony_imu.yaw * RAD_TO_DEG,
             imu_payload.gyro_x_dps, imu_payload.gyro_y_dps, imu_payload.gyro_z_dps);
    }
#elif (PROGRAM_MODE == PROGRAM_MODE_3AXIS_FOLLOW_IMU)
    uint32_t now = HAL_GetTick();
    if (now - last_print_time >= 100) {
      last_print_time = now;
      printf("[AHRS] P:%6.2f R:%6.2f Y:%6.2f (deg) | [TGT] P:%6.2f R:%6.2f Y:%6.2f (deg) | [ENC] P:%6.1f R:%6.1f Y:%6.1f (deg) | [FORCE] P:%5.2f R:%5.2f Y:%5.2f (V)\r\n",
             mahony_imu.pitch * RAD_TO_DEG, mahony_imu.roll * RAD_TO_DEG, mahony_imu.yaw * RAD_TO_DEG,
             imu_pitch_target_rad * RAD_TO_DEG, imu_roll_target_rad * RAD_TO_DEG, imu_yaw_target_rad * RAD_TO_DEG,
             motor_pitch_enc.angle_deg, motor_roll_enc.angle_deg, motor_yaw_enc.angle_deg,
             foc_motor_pitch.Vq_ref, foc_motor_roll.Vq_ref, foc_motor_yaw.Vq_ref);
    }
#elif (PROGRAM_MODE == PROGRAM_MODE_3AXIS_IMU_ON_FRAME)
    uint32_t now = HAL_GetTick();
    if (now - last_print_time >= 100) {
      last_print_time = now;
      float delta_p = (mahony_imu.pitch - imu_pitch_init_rad) * RAD_TO_DEG;
      float delta_r = (mahony_imu.roll - imu_roll_init_rad) * RAD_TO_DEG;
      float delta_y = (mahony_imu.yaw   - imu_yaw_init_rad)   * RAD_TO_DEG;
      printf("[IMU_FRAME] P:%6.2f R:%6.2f Y:%6.2f (deg) | [DELTA] P:%6.2f R:%6.2f Y:%6.2f | [ENC] P:%6.1f R:%6.2f Y:%6.1f | [FORCE] P:%5.2f R:%6.2f Y:%5.2f (V)\r\n",
             mahony_imu.pitch * RAD_TO_DEG, mahony_imu.roll * RAD_TO_DEG, mahony_imu.yaw * RAD_TO_DEG,
             delta_p, delta_r, delta_y,
             motor_pitch_enc.angle_deg, motor_roll_enc.angle_deg, motor_yaw_enc.angle_deg,
             foc_motor_pitch.Vq_ref, foc_motor_roll.Vq_ref, foc_motor_yaw.Vq_ref);
    }
#elif (PROGRAM_MODE == PROGRAM_MODE_TEST_VELOCITY)
    uint32_t now = HAL_GetTick();
    if (now - last_print_time >= 100) {
      last_print_time = now;
      printf("[VEL_TEST] ENC P:%6.1f Y:%6.1f (deg) | VEL P:%6.2f Y:%6.2f (rad/s) | Vq P:%5.2f Y:%5.2f (V)\r\n",
             motor_pitch_enc.angle_deg, motor_yaw_enc.angle_deg,
             foc_motor_pitch.velocity_mech, foc_motor_yaw.velocity_mech,
             foc_motor_pitch.Vq_ref, foc_motor_yaw.Vq_ref);
    }
#elif (PROGRAM_MODE == PROGRAM_MODE_TEST_SBUS)
    /* Gọi SBUS_Process() mỗi vòng lặp — nhanh, chỉ parse khi có frame mới */
    SBUS_Status_t sbus_st = SBUS_Process(&sbus_rx);
    uint32_t now = HAL_GetTick();
    /* In telemetry 10Hz (mỗi 100ms) */
    if (now - last_print_time >= 100) {
      last_print_time = now;

      if (sbus_st == SBUS_OK) {
        /* Đọc 16 kênh raw để hiển thị */
        uint16_t ch1, ch2, ch3, ch4, ch5, ch6, ch7, ch8;
        uint16_t ch9, ch10, ch11, ch12, ch13, ch14, ch15, ch16;
        SBUS_GetChannel(&sbus_rx, 1, &ch1);
        SBUS_GetChannel(&sbus_rx, 2, &ch2);
        SBUS_GetChannel(&sbus_rx, 3, &ch3);
        SBUS_GetChannel(&sbus_rx, 4, &ch4);
        SBUS_GetChannel(&sbus_rx, 5, &ch5);
        SBUS_GetChannel(&sbus_rx, 6, &ch6);
        SBUS_GetChannel(&sbus_rx, 7, &ch7);
        SBUS_GetChannel(&sbus_rx, 8, &ch8);
        SBUS_GetChannel(&sbus_rx, 9, &ch9);
        SBUS_GetChannel(&sbus_rx, 10, &ch10);
        SBUS_GetChannel(&sbus_rx, 11, &ch11);
        SBUS_GetChannel(&sbus_rx, 12, &ch12);
        SBUS_GetChannel(&sbus_rx, 13, &ch13);
        SBUS_GetChannel(&sbus_rx, 14, &ch14);
        SBUS_GetChannel(&sbus_rx, 15, &ch15);
        SBUS_GetChannel(&sbus_rx, 16, &ch16);

        /* Đọc normalized [-1.0..+1.0] cho các kênh điều khiển chính */
        float norm_roll, norm_pitch, norm_throttle, norm_yaw;
        SBUS_GetChannelNorm(&sbus_rx, 1, &norm_roll);  /* CH1: Aileron/Roll   */
        SBUS_GetChannelNorm(&sbus_rx, 2, &norm_pitch); /* CH2: Elevator/Pitch */
        SBUS_GetChannelNorm01(&sbus_rx, 3,
                              &norm_throttle);       /* CH3: Throttle [0..1]*/
        SBUS_GetChannelNorm(&sbus_rx, 4, &norm_yaw); /* CH4: Rudder/Yaw     */

        /* Dòng 1: Raw 16 kênh */
        printf("[SBUS] RAW: %4u %4u %4u %4u %4u %4u %4u %4u "
               "%4u %4u %4u %4u %4u %4u %4u %4u | D:%u%u FS:%u FL:%u\r\n",
               ch1, ch2, ch3, ch4, ch5, ch6, ch7, ch8, ch9, ch10, ch11, ch12,
               ch13, ch14, ch15, ch16, SBUS_GetCH17(&sbus_rx),
               SBUS_GetCH18(&sbus_rx), SBUS_IsFailsafe(&sbus_rx),
               sbus_rx.frame_lost);

        // /* Dòng 2: Normalized 4 kênh chính */
        // printf("[SBUS] NORM: Roll:%+6.3f Pitch:%+6.3f Thr:%5.3f Yaw:%+6.3f\r\n",
        //        norm_roll, norm_pitch, norm_throttle, norm_yaw);

      } else if (sbus_st == SBUS_FAILSAFE) {
        printf("[SBUS] CANH BAO: FAILSAFE dang active! Tat ca kenh ve gia tri "
               "an toan.\r\n");
      } else if (sbus_st == SBUS_FRAME_LOST) {
        printf("[SBUS] CANH BAO: Frame Lost! Tin hieu yeu hoac bi nhieu.\r\n");
      } else if (sbus_st == SBUS_TIMEOUT) {
        printf("[SBUS] LOI: TIMEOUT! Mat tin hieu Receiver (> %dms).\r\n",
               SBUS_TIMEOUT_MS);
      } else {
        printf("[SBUS] Dang cho frame dau tien...\r\n");
      }
    }
#endif
  }
  /* USER CODE END 3 */
}

void SystemClock_Config(void)
{
  RCC_OscInitTypeDef RCC_OscInitStruct = {0};
  RCC_ClkInitTypeDef RCC_ClkInitStruct = {0};

  /** Configure the main internal regulator output voltage
  */
  HAL_PWREx_ControlVoltageScaling(PWR_REGULATOR_VOLTAGE_SCALE1_BOOST);

  /** Initializes the RCC Oscillators according to the specified parameters
  * in the RCC_OscInitTypeDef structure.
  */
  RCC_OscInitStruct.OscillatorType = RCC_OSCILLATORTYPE_HSI|RCC_OSCILLATORTYPE_HSI48;
  RCC_OscInitStruct.HSIState = RCC_HSI_ON;
  RCC_OscInitStruct.HSICalibrationValue = RCC_HSICALIBRATION_DEFAULT;
  RCC_OscInitStruct.HSI48State = RCC_HSI48_ON;
  RCC_OscInitStruct.PLL.PLLState = RCC_PLL_ON;
  RCC_OscInitStruct.PLL.PLLSource = RCC_PLLSOURCE_HSI;
  RCC_OscInitStruct.PLL.PLLM = RCC_PLLM_DIV4;
  RCC_OscInitStruct.PLL.PLLN = 85;
  RCC_OscInitStruct.PLL.PLLP = RCC_PLLP_DIV2;
  RCC_OscInitStruct.PLL.PLLQ = RCC_PLLQ_DIV4;
  RCC_OscInitStruct.PLL.PLLR = RCC_PLLR_DIV2;
  if (HAL_RCC_OscConfig(&RCC_OscInitStruct) != HAL_OK)
  {
    Error_Handler();
  }

  /** Initializes the CPU, AHB and APB buses clocks
  */
  RCC_ClkInitStruct.ClockType = RCC_CLOCKTYPE_HCLK|RCC_CLOCKTYPE_SYSCLK
                              |RCC_CLOCKTYPE_PCLK1|RCC_CLOCKTYPE_PCLK2;
  RCC_ClkInitStruct.SYSCLKSource = RCC_SYSCLKSOURCE_PLLCLK;
  RCC_ClkInitStruct.AHBCLKDivider = RCC_SYSCLK_DIV1;
  RCC_ClkInitStruct.APB1CLKDivider = RCC_HCLK_DIV1;
  RCC_ClkInitStruct.APB2CLKDivider = RCC_HCLK_DIV1;

  if (HAL_RCC_ClockConfig(&RCC_ClkInitStruct, FLASH_LATENCY_4) != HAL_OK)
  {
    Error_Handler();
  }
}

/* USER CODE BEGIN 4 */

/* ============================================================
 * SPI DMA Buffers cho Encoder AS5048A (2-frame pipeline)
 *
 * AS5048A protocol: 2 SPI frames cần thiết để đọc angle
 *   Phase 0: MOSI = READ ANGLE (0xFFFF) → MISO = rác (ignored)
 *   Phase 1: MOSI = NOP (0xC000)         → MISO = angle data
 * ============================================================ */
static uint16_t enc_tx_read_cmd = 0xFFFF; /* READ ANGLE command */
static uint16_t enc_tx_nop_cmd = 0xC000; /* NOP: nhận data từ frame trước */
volatile uint8_t enc_busy = 0;

/* ============================================================
 * SPI DMA Buffers cho ICM42688 (15-byte Burst Read Pipeline)
 * ============================================================ */
static uint8_t icm_tx_buf[15] = {0x1D | 0x80, 0}; /* 0x1D | 0x80: Read command bắt đầu từ TEMP_DATA1 */
static uint8_t icm_rx_buf[15];
volatile uint8_t icm_dma_busy = 0;

void HAL_SPI_TxRxCpltCallback(SPI_HandleTypeDef *hspi) {
  if (hspi->Instance == SPI1) {
    /* Đã chuyển sang dùng Polling trong TIM6 cho hspi1 */
  } else if (hspi->Instance == SPI3) {
    /* SPI3 DMA Burst Read ICM42688 xong (15 bytes) */
    if (imu_payload.cs_port != NULL) {
      HAL_GPIO_WritePin(imu_payload.cs_port, imu_payload.cs_pin, GPIO_PIN_SET);
    } else {
      //HAL_GPIO_WritePin(GPIOC, GPIO_PIN_6, GPIO_PIN_SET);
      HAL_GPIO_WritePin(GPIOC, GPIO_PIN_14, GPIO_PIN_SET);
    }
    icm_dma_busy = 0;

    /* Parse 14-byte data từ icm_rx_buf (byte 0 là dummy/cmd) */
    imu_payload.raw_temp = (int16_t)((icm_rx_buf[1] << 8) | icm_rx_buf[2]);
    imu_payload.raw_accel_x = (int16_t)((icm_rx_buf[3] << 8) | icm_rx_buf[4]);
    imu_payload.raw_accel_y = (int16_t)((icm_rx_buf[5] << 8) | icm_rx_buf[6]);
    imu_payload.raw_accel_z = (int16_t)((icm_rx_buf[7] << 8) | icm_rx_buf[8]);
    imu_payload.raw_gyro_x = (int16_t)((icm_rx_buf[9] << 8) | icm_rx_buf[10]);
    imu_payload.raw_gyro_y = (int16_t)((icm_rx_buf[11] << 8) | icm_rx_buf[12]);
    imu_payload.raw_gyro_z = (int16_t)((icm_rx_buf[13] << 8) | icm_rx_buf[14]);

    float gs = imu_payload.gyro_sensitivity;
    float as = imu_payload.accel_sensitivity;

    float gx = (float)imu_payload.raw_gyro_x / gs;
    float gy = (float)imu_payload.raw_gyro_y / gs;
    float gz = (float)imu_payload.raw_gyro_z / gs;

    if (imu_payload.gyro_calibrated) {
      gx -= imu_payload.gyro_bias_x;
      gy -= imu_payload.gyro_bias_y;
      gz -= imu_payload.gyro_bias_z;
    }

    imu_payload.gyro_x_dps = gx;
    imu_payload.gyro_y_dps = gy;
    imu_payload.gyro_z_dps = gz;

    imu_payload.accel_x_g = (float)imu_payload.raw_accel_x / as;
    imu_payload.accel_y_g = (float)imu_payload.raw_accel_y / as;
    imu_payload.accel_z_g = (float)imu_payload.raw_accel_z / as;
    imu_payload.temp_c = (float)imu_payload.raw_temp / ICM42688_TEMP_SENS + ICM42688_TEMP_OFFSET;

    Mahony_Update(&mahony_imu, imu_payload.gyro_x_dps * DEG_TO_RAD,
                  imu_payload.gyro_y_dps * DEG_TO_RAD,
                  imu_payload.gyro_z_dps * DEG_TO_RAD, imu_payload.accel_x_g,
                  imu_payload.accel_y_g, imu_payload.accel_z_g, 0.0005f);
  }
}

void HAL_TIM_PeriodElapsedCallback(TIM_HandleTypeDef *htim) {
  if (htim->Instance == TIM6) {
    if (!enc_busy) {
      enc_busy = 1;
      uint16_t rx_dummy;
      uint16_t rx_angle_pitch, rx_angle_roll, rx_angle_yaw;

      /* === Phase 0 (Pipeline): Gửi lệnh READ ANGLE cho cả 3 trục liên tiếp === */
      /* PITCH */
      HAL_GPIO_WritePin(ENC_PITCH_CS_GPIO_Port, ENC_PITCH_CS_Pin, GPIO_PIN_RESET);
      HAL_SPI_TransmitReceive(&hspi1, (uint8_t *)&enc_tx_read_cmd, (uint8_t *)&rx_dummy, 1, 2);
      HAL_GPIO_WritePin(ENC_PITCH_CS_GPIO_Port, ENC_PITCH_CS_Pin, GPIO_PIN_SET);

      /* ROLL */
      HAL_GPIO_WritePin(ENC_ROLL_CS_GPIO_Port, ENC_ROLL_CS_Pin, GPIO_PIN_RESET);
      HAL_SPI_TransmitReceive(&hspi1, (uint8_t *)&enc_tx_read_cmd, (uint8_t *)&rx_dummy, 1, 2);
      HAL_GPIO_WritePin(ENC_ROLL_CS_GPIO_Port, ENC_ROLL_CS_Pin, GPIO_PIN_SET);

      /* YAW */
      HAL_GPIO_WritePin(ENC_YAW_CS_GPIO_Port, ENC_YAW_CS_Pin, GPIO_PIN_RESET);
      HAL_SPI_TransmitReceive(&hspi1, (uint8_t *)&enc_tx_read_cmd, (uint8_t *)&rx_dummy, 1, 2);
      HAL_GPIO_WritePin(ENC_YAW_CS_GPIO_Port, ENC_YAW_CS_Pin, GPIO_PIN_SET);

      /* === Phase 1 (Pipeline): Gửi lệnh NOP để clock ra Data góc === */
      /* PITCH */
      HAL_GPIO_WritePin(ENC_PITCH_CS_GPIO_Port, ENC_PITCH_CS_Pin, GPIO_PIN_RESET);
      HAL_SPI_TransmitReceive(&hspi1, (uint8_t *)&enc_tx_nop_cmd, (uint8_t *)&rx_angle_pitch, 1, 2);
      HAL_GPIO_WritePin(ENC_PITCH_CS_GPIO_Port, ENC_PITCH_CS_Pin, GPIO_PIN_SET);

      /* ROLL */
      HAL_GPIO_WritePin(ENC_ROLL_CS_GPIO_Port, ENC_ROLL_CS_Pin, GPIO_PIN_RESET);
      HAL_SPI_TransmitReceive(&hspi1, (uint8_t *)&enc_tx_nop_cmd, (uint8_t *)&rx_angle_roll, 1, 2);
      HAL_GPIO_WritePin(ENC_ROLL_CS_GPIO_Port, ENC_ROLL_CS_Pin, GPIO_PIN_SET);

      /* YAW */
      HAL_GPIO_WritePin(ENC_YAW_CS_GPIO_Port, ENC_YAW_CS_Pin, GPIO_PIN_RESET);
      HAL_SPI_TransmitReceive(&hspi1, (uint8_t *)&enc_tx_nop_cmd, (uint8_t *)&rx_angle_yaw, 1, 2);
      HAL_GPIO_WritePin(ENC_YAW_CS_GPIO_Port, ENC_YAW_CS_Pin, GPIO_PIN_SET);

      /* === Xử lý Parity và tính Góc === */
      if (AS5048A_CheckParity(rx_angle_pitch)) {
        motor_pitch_enc.raw_angle = rx_angle_pitch & AS5048A_DATA_MASK;
        motor_pitch_enc.angle_rad = (float)motor_pitch_enc.raw_angle * (TWO_PI / AS5048A_MAX_VALUE);
        motor_pitch_enc.angle_deg = (float)motor_pitch_enc.raw_angle * (360.0f / AS5048A_MAX_VALUE);
      }
      if (AS5048A_CheckParity(rx_angle_roll)) {
        motor_roll_enc.raw_angle = rx_angle_roll & AS5048A_DATA_MASK;
        motor_roll_enc.angle_rad = (float)motor_roll_enc.raw_angle * (TWO_PI / AS5048A_MAX_VALUE);
        motor_roll_enc.angle_deg = (float)motor_roll_enc.raw_angle * (360.0f / AS5048A_MAX_VALUE);
      }
      if (AS5048A_CheckParity(rx_angle_yaw)) {
        motor_yaw_enc.raw_angle = rx_angle_yaw & AS5048A_DATA_MASK;
        motor_yaw_enc.angle_rad = (float)motor_yaw_enc.raw_angle * (TWO_PI / AS5048A_MAX_VALUE);
        motor_yaw_enc.angle_deg = (float)motor_yaw_enc.raw_angle * (360.0f / AS5048A_MAX_VALUE);
      }

      enc_busy = 0;
    }
    /* TIM6: Kích hoạt SPI3 DMA đọc Burst 15-byte cho ICM42688 (SPI3) */
    if (!icm_dma_busy && icm_init_ok) {
      icm_dma_busy = 1;
      //HAL_GPIO_WritePin(GPIOC, GPIO_PIN_6, GPIO_PIN_RESET);
      HAL_GPIO_WritePin(GPIOC, GPIO_PIN_14, GPIO_PIN_RESET);
      if (HAL_SPI_TransmitReceive_DMA(&hspi3, icm_tx_buf, icm_rx_buf, 15) != HAL_OK) {
        icm_dma_busy = 0;
        //HAL_GPIO_WritePin(GPIOC, GPIO_PIN_6, GPIO_PIN_SET);
        HAL_GPIO_WritePin(GPIOC, GPIO_PIN_14, GPIO_PIN_SET);
      }
    }

  } else if (htim->Instance == TIM16) {
#if (PROGRAM_MODE == PROGRAM_MODE_3AXIS_IMU_ON_FRAME)
#else
    /* Outer loop @ 500Hz: IMU angle error → velocity setpoint [rad/s] cho FOC_VelocityLoop */
    if (icm_init_ok) {
      /* Sai số: target chốt lúc startup - góc IMU thực tế
       * Khi frame nghiêng pitch tăng → error âm → velocity âm → motor bù ngược lại */
      float imu_error_pitch = imu_pitch_target_rad - mahony_imu.pitch;
      float imu_error_roll = -imu_roll_target_rad + mahony_imu.roll;
      float imu_error_yaw   = -imu_yaw_target_rad   + mahony_imu.yaw;

      /* Wrap về [-π, +π]: chọn hướng bù ngắn nhất (quan trọng cho Yaw) */
      if (imu_error_pitch >  PI) imu_error_pitch -= TWO_PI;
      if (imu_error_pitch < -PI) imu_error_pitch += TWO_PI;
      if (imu_error_roll >  PI) imu_error_roll -= TWO_PI;
      if (imu_error_roll < -PI) imu_error_roll += TWO_PI;
      if (imu_error_yaw   >  PI) imu_error_yaw   -= TWO_PI;
      if (imu_error_yaw   < -PI) imu_error_yaw   += TWO_PI;

      /* PID → velocity setpoint [rad/s] */
      imu_stab_vel_pitch = PID_Update(&pid_imu_pitch_pos, imu_error_pitch, 0.002f);
      imu_stab_vel_roll = PID_Update(&pid_imu_roll_pos, imu_error_roll, 0.002f);
      imu_stab_vel_yaw   = PID_Update(&pid_imu_yaw_pos,   imu_error_yaw,   0.002f);
    }
#endif
  } else if (htim->Instance == TIM7) {
#if (PROGRAM_MODE == PROGRAM_MODE_3AXIS_FOLLOW_IMU)
    /* ================================================================
     * 3AXIS_FOLLOW_IMU: Vòng trong (2kHz) dùng FOC_VelocityLoop
     * Velocity setpoint được tính từ outer loop (TIM16 @ 500Hz)
     * ================================================================ */
    FOC_VelocityLoop(&foc_motor_pitch, motor_pitch_enc.angle_rad, imu_stab_vel_pitch);
    FOC_VelocityLoop(&foc_motor_roll, motor_roll_enc.angle_rad, imu_stab_vel_roll);
    FOC_VelocityLoop(&foc_motor_yaw, motor_yaw_enc.angle_rad, imu_stab_vel_yaw);
#elif (PROGRAM_MODE == PROGRAM_MODE_3AXIS_IMU_ON_FRAME)
    /* ================================================================
     * IMU_ON_FRAME: IMU đặt trên frame — bù delta góc (2kHz)
     * Khi frame xoay α → target motor = motor_init - α → giữ payload cố định
     * ================================================================ */
    if (icm_init_ok) {
      /* Tính lượng frame đã lệch từ điểm tham chiếu khởi động */
      float delta_pitch = mahony_imu.pitch - imu_pitch_init_rad;
      float delta_roll = mahony_imu.roll - imu_roll_init_rad;
      float delta_yaw   = mahony_imu.yaw   - imu_yaw_init_rad;

      /* Wrap về [-π, +π] để xử lý đúng vùng qua 0°/360° */
      if (delta_pitch >  PI) delta_pitch -= TWO_PI;
      if (delta_pitch < -PI) delta_pitch += TWO_PI;
      if (delta_roll >  PI) delta_roll -= TWO_PI;
      if (delta_roll < -PI) delta_roll += TWO_PI;
      if (delta_yaw   >  PI) delta_yaw   -= TWO_PI;
      if (delta_yaw   < -PI) delta_yaw   += TWO_PI;

      /* Cập nhật target motor = vị trí ban đầu - delta (bù ngược chiều frame) */
      target_motor_pitch_imu = DEG2RAD(HOME_MOTOR_PITCH_DEG) + delta_pitch;
      target_motor_roll_imu  = DEG2RAD(HOME_MOTOR_ROLL_DEG)  + delta_roll;
      target_motor_yaw_imu   = DEG2RAD(HOME_MOTOR_YAW_DEG)   + delta_yaw;

      /* FOC Position Loop: encoder làm phản hồi, giữ motor tại target */
      FOC_PositionLoop(&foc_motor_pitch, motor_pitch_enc.angle_rad, target_motor_pitch_imu);
      FOC_PositionLoop(&foc_motor_roll, motor_roll_enc.angle_rad, target_motor_roll_imu);
      FOC_PositionLoop(&foc_motor_yaw,   motor_yaw_enc.angle_rad,   target_motor_yaw_imu);
    }
#elif (PROGRAM_MODE == PROGRAM_MODE_TEST_VELOCITY)
    /* Test Velocity: Quay với tốc độ 1.0 rad/s */
    FOC_VelocityLoop(&foc_motor_pitch, motor_pitch_enc.angle_rad, 7.0f);
    FOC_VelocityLoop(&foc_motor_yaw, motor_yaw_enc.angle_rad, 7.0f);
#else
    /* ================================================================
     * PROGRAM_MODE_MAIN: Tach hai nhánh SBUS/HOMING va IMU_STAB
     * ================================================================ */

    const float pitch_min_rad = DEG2RAD(MOTOR_PITCH_MIN_DEG);
    const float pitch_max_rad = DEG2RAD(MOTOR_PITCH_MAX_DEG);
    const float roll_min_rad = DEG2RAD(MOTOR_ROLL_MIN_DEG);
    const float roll_max_rad = DEG2RAD(MOTOR_ROLL_MAX_DEG);
    // const float yaw_min_rad = DEG2RAD(MOTOR_YAW_MIN_DEG);
    // const float yaw_max_rad = DEG2RAD(MOTOR_YAW_MAX_DEG);
    const float yaw_forbid_min_rad = DEG2RAD(MOTOR_YAW_FORBIDDEN_MIN_DEG);
    const float yaw_forbid_max_rad = DEG2RAD(MOTOR_YAW_FORBIDDEN_MAX_DEG);

    if (target_motor_pitch_angle < pitch_min_rad)
      target_motor_pitch_angle = pitch_min_rad;
    if (target_motor_pitch_angle > pitch_max_rad)
      target_motor_pitch_angle = pitch_max_rad;
    if (target_motor_roll_angle < roll_min_rad)
      target_motor_roll_angle = roll_min_rad;
    if (target_motor_roll_angle > roll_max_rad)
      target_motor_roll_angle = roll_max_rad;
    // if (target_motor_yaw_angle < yaw_min_rad)
    //   target_motor_yaw_angle = yaw_min_rad;
    // if (target_motor_yaw_angle > yaw_max_rad)
    //   target_motor_yaw_angle = yaw_max_rad;

    // Kiểm tra xem target có bị rơi vào vùng cấm không (từ 65 độ -> 225 độ)
    if (target_motor_yaw_angle > yaw_forbid_min_rad && target_motor_yaw_angle < yaw_forbid_max_rad) {
      float dist_to_min = target_motor_yaw_angle - yaw_forbid_min_rad;
      float dist_to_max = yaw_forbid_max_rad - target_motor_yaw_angle;
      if (dist_to_min < dist_to_max) {
        target_motor_yaw_angle = yaw_forbid_min_rad; // Đẩy về 65 độ
      } else {
        target_motor_yaw_angle = yaw_forbid_max_rad; // Đẩy về 225 độ
      }
    }

    FOC_PositionLoop(&foc_motor_pitch, motor_pitch_enc.angle_rad, target_motor_pitch_angle);
    //FOC_PositionLoop(&foc_motor_roll,  motor_roll_enc.angle_rad,  target_motor_roll_angle);
    FOC_PositionLoop(&foc_motor_yaw,   motor_yaw_enc.angle_rad,   target_motor_yaw_angle);

#endif
  }
}

/* USER CODE END 4 */

void Error_Handler(void)
{
}
